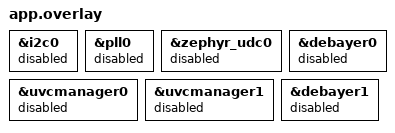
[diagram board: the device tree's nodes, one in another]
/*
 * Copyright (c) 2024-2025 tinyVision.ai Inc.
 *
 * SPDX-License-Identifier: Apache-2.0
 */

&i2c0 {
	status = "disabled";
};

&pll0 {
	status = "disabled";
};

&zephyr_udc0 {
	status = "disabled";
};

&uvcmanager0 {
	status = "disabled";
};

&debayer0 {
	status = "disabled";
};

&uvcmanager1 {
	status = "disabled";
};

&debayer1 {
	status = "disabled";
};
